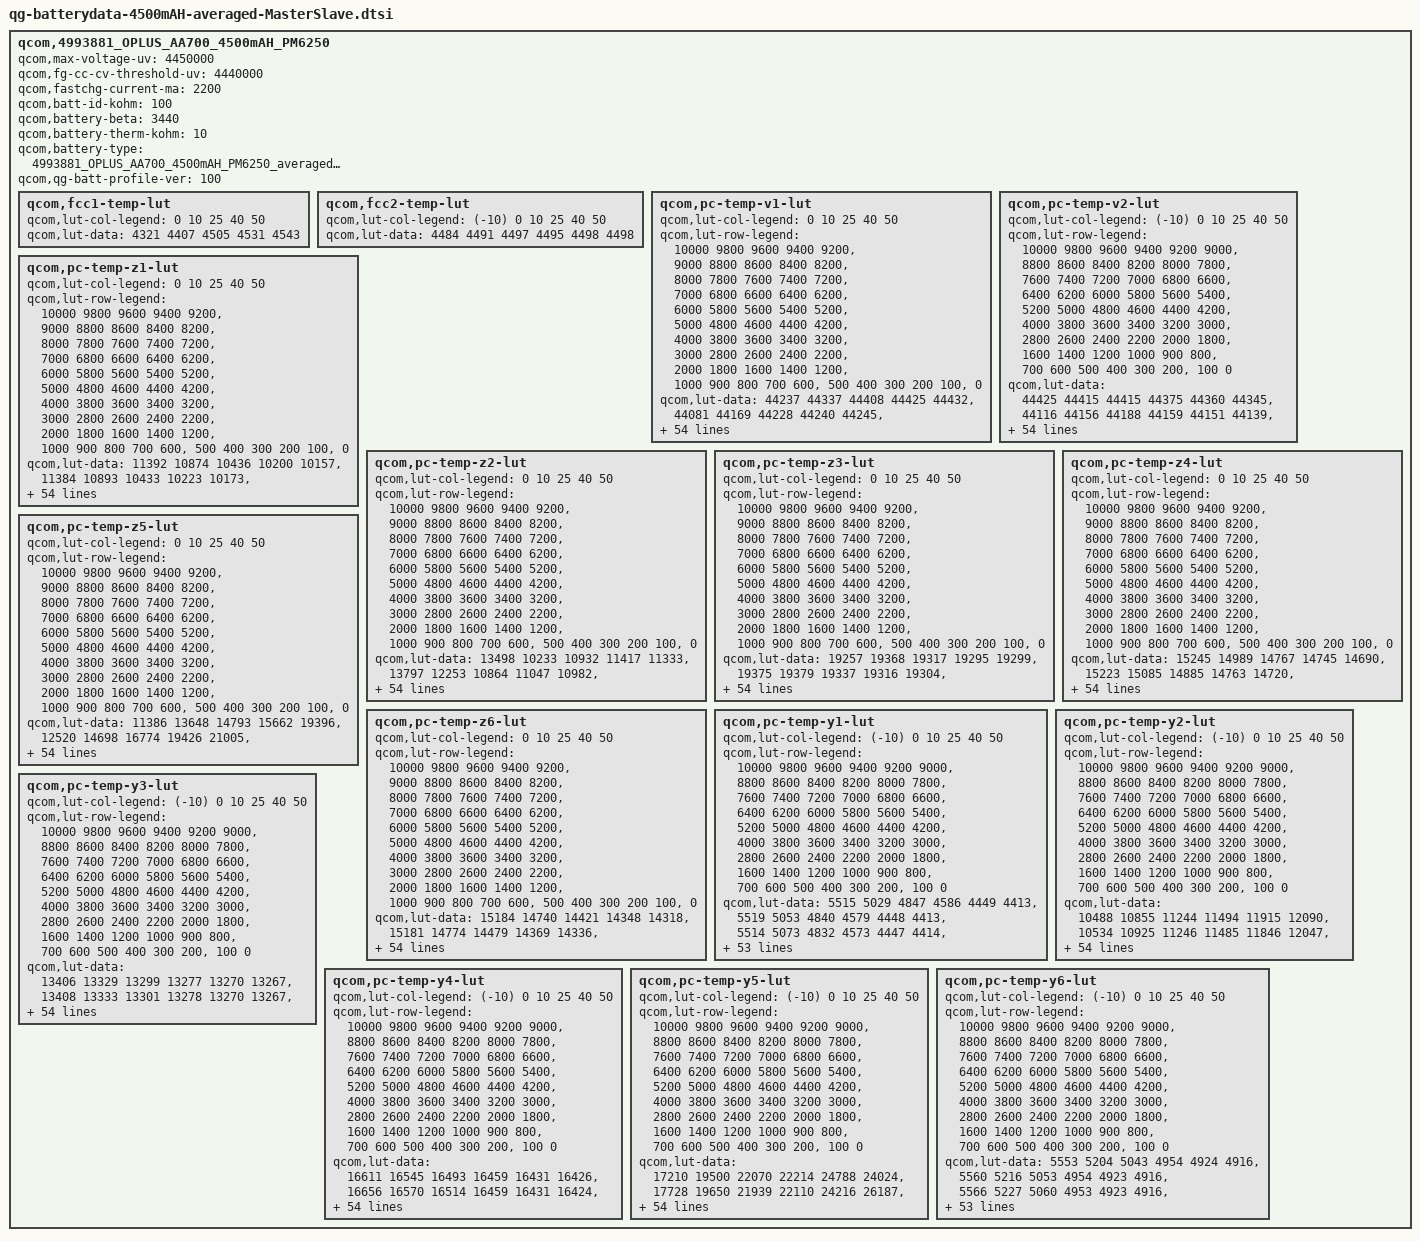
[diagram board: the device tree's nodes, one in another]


qcom,4993881_OPLUS_AA700_4500mAH_PM6250 {
    /* 4993881_OPLUS_AA700_4500mAH_PM6250_averaged_MasterSlave_Feb2th2021 */
    qcom,max-voltage-uv = <4450000>;
    qcom,fg-cc-cv-threshold-uv = <4440000>;
    qcom,fastchg-current-ma = <2200>;
    qcom,batt-id-kohm = <100>;
    qcom,battery-beta = <3440>;
    qcom,battery-therm-kohm = <10>;
    qcom,battery-type = "4993881_OPLUS_AA700_4500mAH_PM6250_averaged_MasterSlave_Feb2th2021";
    qcom,qg-batt-profile-ver = <100>;

	qcom,fcc1-temp-lut {
		qcom,lut-col-legend = <0 10 25 40 50>;
		qcom,lut-data = <4321 4407 4505 4531 4543>;
	};

	qcom,fcc2-temp-lut {
		qcom,lut-col-legend = <(-10) 0 10 25 40 50>;
		qcom,lut-data = <4484 4491 4497 4495 4498 4498>;
	};

	qcom,pc-temp-v1-lut {
		qcom,lut-col-legend = <0 10 25 40 50>;
		qcom,lut-row-legend = <10000 9800 9600 9400 9200>,
			<9000 8800 8600 8400 8200>,
			<8000 7800 7600 7400 7200>,
			<7000 6800 6600 6400 6200>,
			<6000 5800 5600 5400 5200>,
			<5000 4800 4600 4400 4200>,
			<4000 3800 3600 3400 3200>,
			<3000 2800 2600 2400 2200>,
			<2000 1800 1600 1400 1200>,
			<1000 900 800 700 600>,
			<500 400 300 200 100>,
			<0>;
		qcom,lut-data = <44237 44337 44408 44425 44432>,
			<44081 44169 44228 44240 44245>,
			<43870 43985 44048 44060 44064>,
			<43642 43785 43860 43875 43880>,
			<43419 43574 43663 43680 43689>,
			<43193 43355 43456 43476 43489>,
			<42962 43127 43233 43260 43276>,
			<42726 42893 42999 43032 43049>,
			<42489 42653 42762 42798 42816>,
			<42256 42411 42517 42556 42578>,
			<42025 42172 42273 42311 42338>,
			<41799 41935 42032 42071 42098>,
			<41577 41704 41793 41834 41858>,
			<41362 41479 41560 41599 41622>,
			<41154 41260 41333 41369 41390>,
			<40957 41052 41113 41143 41163>,
			<40760 40850 40900 40925 40944>,
			<40558 40651 40694 40715 40734>,
			<40356 40462 40497 40514 40532>,
			<40150 40269 40317 40330 40345>,
			<39937 40046 40122 40140 40156>,
			<39724 39787 39868 39902 39927>,
			<39514 39555 39592 39632 39661>,
			<39302 39367 39377 39406 39430>,
			<39138 39204 39207 39225 39245>,
			<39033 39062 39058 39068 39084>,
			<38949 38937 38926 38930 38942>,
			<38863 38826 38808 38807 38815>,
			<38776 38725 38698 38693 38698>,
			<38692 38632 38595 38586 38588>,
			<38616 38549 38502 38487 38486>,
			<38544 38473 38418 38397 38392>,
			<38480 38404 38342 38314 38305>,
			<38423 38343 38274 38240 38225>,
			<38371 38288 38214 38175 38155>,
			<38327 38236 38157 38109 38083>,
			<38289 38193 38102 38037 37996>,
			<38240 38144 38046 37957 37899>,
			<38155 38066 37970 37869 37799>,
			<38038 37954 37867 37770 37696>,
			<37910 37830 37750 37659 37584>,
			<37762 37696 37622 37529 37450>,
			<37595 37545 37478 37383 37303>,
			<37406 37361 37297 37212 37139>,
			<37306 37210 37152 37082 37014>,
			<37220 37128 37078 37015 36956>,
			<37187 37102 37054 36996 36938>,
			<37156 37083 37035 36985 36924>,
			<37114 37057 37005 36957 36892>,
			<36985 36954 36869 36795 36698>,
			<36604 36603 36502 36434 36324>,
			<36097 36118 36016 35951 35838>,
			<35446 35490 35384 35331 35207>,
			<34546 34625 34511 34457 34336>,
			<33087 33238 33127 33104 32965>,
			<30000 30000 30000 30000 30000>;
	};

	qcom,pc-temp-v2-lut {
		qcom,lut-col-legend = <(-10) 0 10 25 40 50>;
		qcom,lut-row-legend = <10000 9800 9600 9400 9200 9000>,
			<8800 8600 8400 8200 8000 7800>,
			<7600 7400 7200 7000 6800 6600>,
			<6400 6200 6000 5800 5600 5400>,
			<5200 5000 4800 4600 4400 4200>,
			<4000 3800 3600 3400 3200 3000>,
			<2800 2600 2400 2200 2000 1800>,
			<1600 1400 1200 1000 900 800>,
			<700 600 500 400 300 200>,
			<100 0>;
		qcom,lut-data = <44425 44415 44415 44375 44360 44345>,
			<44116 44156 44188 44159 44151 44139>,
			<43830 43912 43968 43947 43944 43934>,
			<43572 43688 43760 43741 43741 43732>,
			<43341 43484 43566 43542 43542 43532>,
			<43113 43276 43363 43336 43335 43325>,
			<42879 43048 43139 43113 43113 43104>,
			<42643 42810 42904 42879 42881 42873>,
			<42399 42570 42667 42642 42646 42640>,
			<42143 42327 42424 42398 42405 42399>,
			<41888 42084 42181 42155 42164 42159>,
			<41628 41842 41942 41915 41925 41921>,
			<41378 41602 41705 41677 41688 41684>,
			<41189 41367 41470 41444 41455 41452>,
			<41057 41135 41239 41217 41227 41225>,
			<40900 40919 41014 40995 41004 41003>,
			<40612 40740 40804 40781 40790 40787>,
			<40241 40568 40599 40573 40582 40578>,
			<39941 40342 40385 40371 40383 40379>,
			<39695 40042 40165 40180 40194 40193>,
			<39466 39746 39931 39973 39990 39990>,
			<39240 39492 39665 39710 39730 39731>,
			<39023 39258 39394 39429 39455 39456>,
			<38821 39054 39178 39209 39239 39243>,
			<38623 38872 39001 39030 39063 39071>,
			<38462 38710 38843 38874 38909 38921>,
			<38351 38567 38701 38737 38775 38787>,
			<38263 38438 38572 38616 38655 38666>,
			<38188 38314 38454 38502 38542 38553>,
			<38124 38190 38344 38397 38436 38447>,
			<38065 38089 38244 38300 38339 38349>,
			<38008 38019 38150 38211 38251 38259>,
			<37954 37962 38064 38128 38170 38175>,
			<37895 37912 37982 38048 38088 38089>,
			<37835 37869 37904 37972 38007 38005>,
			<37770 37827 37834 37892 37918 37909>,
			<37700 37786 37778 37802 37805 37782>,
			<37624 37742 37726 37705 37681 37641>,
			<37540 37680 37658 37610 37572 37524>,
			<37446 37588 37574 37518 37476 37427>,
			<37340 37475 37473 37417 37373 37325>,
			<37213 37331 37348 37303 37254 37203>,
			<37077 37162 37202 37173 37121 37068>,
			<36960 36977 37028 37002 36953 36900>,
			<36858 36843 36908 36908 36873 36825>,
			<36771 36774 36845 36873 36847 36801>,
			<36730 36742 36819 36856 36832 36785>,
			<36681 36707 36789 36829 36809 36760>,
			<36603 36647 36737 36782 36764 36700>,
			<36443 36482 36583 36627 36571 36454>,
			<36116 36111 36215 36249 36169 36031>,
			<35619 35566 35674 35723 35637 35483>,
			<34920 34851 34968 35050 34947 34761>,
			<33929 33850 33986 34122 33992 33773>,
			<32235 32088 32385 32620 32537 32234>,
			<27198 27147 28411 28035 28518 28018>;
	};

	qcom,pc-temp-z1-lut {
		qcom,lut-col-legend = <0 10 25 40 50>;
		qcom,lut-row-legend = <10000 9800 9600 9400 9200>,
			<9000 8800 8600 8400 8200>,
			<8000 7800 7600 7400 7200>,
			<7000 6800 6600 6400 6200>,
			<6000 5800 5600 5400 5200>,
			<5000 4800 4600 4400 4200>,
			<4000 3800 3600 3400 3200>,
			<3000 2800 2600 2400 2200>,
			<2000 1800 1600 1400 1200>,
			<1000 900 800 700 600>,
			<500 400 300 200 100>,
			<0>;
		qcom,lut-data = <11392 10874 10436 10200 10157>,
			<11384 10893 10433 10223 10173>,
			<11404 10895 10450 10230 10177>,
			<11419 10888 10452 10232 10178>,
			<11411 10878 10443 10230 10178>,
			<11389 10866 10432 10228 10178>,
			<11364 10852 10427 10226 10177>,
			<11331 10838 10424 10225 10176>,
			<11299 10825 10419 10223 10175>,
			<11280 10815 10414 10221 10174>,
			<11265 10809 10410 10219 10173>,
			<11257 10805 10408 10218 10173>,
			<11251 10801 10406 10218 10173>,
			<11246 10797 10405 10218 10173>,
			<11244 10793 10404 10217 10173>,
			<11242 10794 10403 10217 10173>,
			<11240 10800 10403 10217 10173>,
			<11242 10802 10403 10217 10173>,
			<11251 10794 10403 10217 10174>,
			<11255 10785 10406 10218 10174>,
			<11243 10792 10409 10220 10176>,
			<11229 10830 10411 10220 10176>,
			<11228 10854 10413 10220 10177>,
			<11232 10839 10415 10221 10178>,
			<11235 10814 10417 10222 10179>,
			<11236 10809 10420 10223 10181>,
			<11237 10805 10425 10225 10182>,
			<11239 10804 10431 10228 10182>,
			<11248 10809 10434 10230 10184>,
			<11256 10815 10436 10233 10185>,
			<11254 10817 10437 10235 10187>,
			<11250 10815 10440 10237 10189>,
			<11248 10814 10444 10239 10190>,
			<11250 10817 10449 10241 10191>,
			<11253 10823 10456 10244 10194>,
			<11257 10829 10463 10247 10196>,
			<11263 10837 10469 10250 10198>,
			<11271 10845 10474 10253 10200>,
			<11288 10851 10478 10255 10202>,
			<11310 10858 10481 10258 10203>,
			<11316 10862 10485 10260 10204>,
			<11304 10874 10490 10260 10205>,
			<11302 10882 10494 10261 10205>,
			<11310 10880 10497 10262 10206>,
			<11321 10887 10502 10264 10207>,
			<11317 10880 10505 10264 10207>,
			<11326 10901 10507 10265 10206>,
			<11340 10894 10516 10266 10208>,
			<11344 10893 10512 10268 10208>,
			<11343 10894 10519 10269 10209>,
			<11346 10896 10529 10271 10212>,
			<11356 10908 10531 10275 10213>,
			<11392 10915 10538 10279 10216>,
			<11380 10933 10542 10284 10220>,
			<11380 10933 10542 10284 10220>,
			<11380 10933 10542 10284 10220>;
	};

	qcom,pc-temp-z2-lut {
		qcom,lut-col-legend = <0 10 25 40 50>;
		qcom,lut-row-legend = <10000 9800 9600 9400 9200>,
			<9000 8800 8600 8400 8200>,
			<8000 7800 7600 7400 7200>,
			<7000 6800 6600 6400 6200>,
			<6000 5800 5600 5400 5200>,
			<5000 4800 4600 4400 4200>,
			<4000 3800 3600 3400 3200>,
			<3000 2800 2600 2400 2200>,
			<2000 1800 1600 1400 1200>,
			<1000 900 800 700 600>,
			<500 400 300 200 100>,
			<0>;
		qcom,lut-data = <13498 10233 10932 11417 11333>,
			<13797 12253 10864 11047 10982>,
			<11927 12575 10864 10953 11035>,
			<10471 11519 10844 10906 11073>,
			<10397 10623 10795 10872 11052>,
			<10387 10560 10757 10852 11016>,
			<10375 10520 10749 10857 11010>,
			<10355 10509 10744 10881 11015>,
			<10337 10508 10739 10893 11021>,
			<10330 10509 10736 10887 11036>,
			<10326 10516 10737 10883 11057>,
			<10324 10532 10741 10891 11065>,
			<10340 10540 10744 10908 11072>,
			<10369 10541 10736 10927 11081>,
			<10385 10541 10717 10953 11092>,
			<10394 10543 10698 10974 11107>,
			<10402 10550 10681 10973 11132>,
			<10410 10556 10666 10966 11172>,
			<10418 10561 10665 10960 11195>,
			<10430 10569 10678 10951 11193>,
			<10454 11228 10695 10943 11182>,
			<10475 13969 10717 10949 11161>,
			<10467 15631 10743 10964 11118>,
			<10425 13871 10764 10963 11064>,
			<10399 11170 10783 10874 10970>,
			<10411 10582 10794 10779 10888>,
			<10432 10567 10762 10754 10873>,
			<10439 10560 10706 10740 10873>,
			<10439 10557 10694 10741 10881>,
			<10439 10556 10700 10790 10935>,
			<10445 10561 10710 10850 11006>,
			<10460 10581 10744 10885 11060>,
			<10472 10602 10796 10915 11110>,
			<10483 10615 10819 10940 11138>,
			<10491 10626 10828 10960 11156>,
			<10491 10632 10835 10982 11176>,
			<10489 10634 10844 11024 11235>,
			<10488 10637 10854 11078 11323>,
			<10492 10650 10878 11118 11345>,
			<10499 10680 10936 11171 11327>,
			<10496 10691 10972 11204 11305>,
			<10474 10647 10919 11167 11287>,
			<10466 10614 10857 11104 11262>,
			<10472 10610 10867 11072 11199>,
			<14727 10645 10873 11073 11187>,
			<14065 10663 10878 11146 11248>,
			<16754 10642 10876 11144 11289>,
			<17754 10623 10803 11214 11332>,
			<18890 10616 10848 11179 11414>,
			<17901 10680 10865 11017 11094>,
			<14975 10727 10840 10939 10998>,
			<15650 10776 10792 10914 10932>,
			<12253 10753 10790 10852 10891>,
			<11025 10756 10700 10788 10813>,
			<11025 10756 10700 10788 10813>,
			<11025 10756 10700 10788 10813>;
	};

	qcom,pc-temp-z3-lut {
		qcom,lut-col-legend = <0 10 25 40 50>;
		qcom,lut-row-legend = <10000 9800 9600 9400 9200>,
			<9000 8800 8600 8400 8200>,
			<8000 7800 7600 7400 7200>,
			<7000 6800 6600 6400 6200>,
			<6000 5800 5600 5400 5200>,
			<5000 4800 4600 4400 4200>,
			<4000 3800 3600 3400 3200>,
			<3000 2800 2600 2400 2200>,
			<2000 1800 1600 1400 1200>,
			<1000 900 800 700 600>,
			<500 400 300 200 100>,
			<0>;
		qcom,lut-data = <19257 19368 19317 19295 19299>,
			<19375 19379 19337 19316 19304>,
			<19477 19392 19358 19321 19310>,
			<19541 19428 19368 19325 19313>,
			<19561 19458 19374 19330 19314>,
			<19572 19463 19377 19334 19315>,
			<19575 19467 19375 19333 19315>,
			<19576 19467 19372 19329 19315>,
			<19576 19463 19369 19325 19313>,
			<19575 19458 19367 19325 19311>,
			<19572 19455 19365 19324 19307>,
			<19568 19454 19364 19321 19306>,
			<19561 19452 19363 19317 19305>,
			<19554 19449 19360 19314 19305>,
			<19548 19445 19356 19314 19304>,
			<19542 19442 19352 19313 19304>,
			<19538 19439 19351 19312 19302>,
			<19536 19436 19350 19311 19298>,
			<19535 19434 19349 19310 19295>,
			<19535 19432 19347 19309 19294>,
			<19544 19430 19347 19308 19294>,
			<19555 19428 19347 19311 19298>,
			<19556 19428 19350 19322 19311>,
			<19549 19429 19355 19328 19317>,
			<19544 19434 19371 19331 19317>,
			<19542 19440 19382 19333 19317>,
			<19541 19453 19380 19332 19316>,
			<19541 19462 19378 19330 19314>,
			<19541 19459 19375 19329 19312>,
			<19542 19454 19371 19326 19310>,
			<19541 19449 19368 19324 19308>,
			<19538 19445 19364 19321 19306>,
			<19535 19441 19361 19317 19303>,
			<19534 19439 19359 19315 19301>,
			<19532 19437 19358 19313 19298>,
			<19530 19436 19357 19312 19296>,
			<19527 19435 19357 19312 19297>,
			<19524 19435 19357 19314 19301>,
			<19518 19433 19357 19315 19303>,
			<19512 19427 19355 19316 19306>,
			<19508 19423 19352 19316 19307>,
			<19506 19420 19348 19316 19306>,
			<19503 19416 19345 19317 19305>,
			<19496 19411 19345 19318 19305>,
			<19301 19401 19341 19315 19304>,
			<19257 19392 19331 19306 19295>,
			<19257 19391 19331 19306 19294>,
			<19257 19385 19330 19299 19291>,
			<19256 19377 19330 19299 19290>,
			<19256 19374 19332 19311 19301>,
			<19257 19373 19341 19314 19302>,
			<19257 19349 19338 19315 19302>,
			<19258 19340 19331 19313 19302>,
			<19259 19333 19339 19317 19306>,
			<19259 19333 19339 19317 19306>,
			<19259 19333 19339 19317 19306>;
	};

	qcom,pc-temp-z4-lut {
		qcom,lut-col-legend = <0 10 25 40 50>;
		qcom,lut-row-legend = <10000 9800 9600 9400 9200>,
			<9000 8800 8600 8400 8200>,
			<8000 7800 7600 7400 7200>,
			<7000 6800 6600 6400 6200>,
			<6000 5800 5600 5400 5200>,
			<5000 4800 4600 4400 4200>,
			<4000 3800 3600 3400 3200>,
			<3000 2800 2600 2400 2200>,
			<2000 1800 1600 1400 1200>,
			<1000 900 800 700 600>,
			<500 400 300 200 100>,
			<0>;
		qcom,lut-data = <15245 14989 14767 14745 14690>,
			<15223 15085 14885 14763 14720>,
			<15219 15094 14864 14750 14712>,
			<15214 15030 14838 14735 14701>,
			<15173 14955 14801 14712 14686>,
			<15076 14901 14766 14691 14669>,
			<14994 14852 14741 14681 14661>,
			<14934 14812 14720 14675 14657>,
			<14884 14776 14708 14670 14654>,
			<14844 14751 14701 14665 14652>,
			<14809 14742 14695 14660 14650>,
			<14786 14736 14688 14656 14647>,
			<14773 14732 14682 14654 14642>,
			<14763 14729 14678 14650 14638>,
			<14759 14727 14676 14645 14633>,
			<14757 14725 14674 14640 14629>,
			<14755 14722 14672 14636 14626>,
			<14762 14721 14669 14633 14624>,
			<14778 14723 14668 14631 14622>,
			<14790 14728 14668 14630 14620>,
			<14797 14742 14668 14629 14619>,
			<14805 14779 14701 14643 14626>,
			<14825 14806 14761 14679 14651>,
			<14866 14817 14772 14692 14663>,
			<14889 14824 14750 14686 14661>,
			<14875 14820 14727 14677 14657>,
			<14848 14791 14715 14671 14653>,
			<14830 14767 14706 14664 14648>,
			<14817 14762 14701 14659 14644>,
			<14809 14759 14696 14654 14640>,
			<14807 14759 14695 14650 14637>,
			<14806 14760 14695 14648 14634>,
			<14806 14761 14695 14647 14631>,
			<14807 14762 14696 14646 14631>,
			<14807 14762 14698 14647 14631>,
			<14804 14762 14701 14648 14631>,
			<14798 14759 14704 14654 14636>,
			<14791 14755 14708 14664 14645>,
			<14784 14752 14709 14666 14647>,
			<14777 14747 14706 14663 14644>,
			<14766 14741 14702 14659 14640>,
			<14748 14725 14691 14653 14638>,
			<14729 14708 14678 14647 14636>,
			<14710 14695 14672 14645 14636>,
			<14840 14668 14658 14640 14630>,
			<14863 14644 14640 14629 14622>,
			<14860 14638 14630 14621 14616>,
			<14855 14638 14623 14618 14610>,
			<14853 14640 14620 14614 14609>,
			<14852 14645 14626 14615 14612>,
			<14858 14651 14620 14614 14613>,
			<14860 14677 14622 14614 14613>,
			<14866 14690 14627 14615 14613>,
			<14873 14699 14621 14614 14613>,
			<14873 14699 14621 14614 14613>,
			<14873 14699 14621 14614 14613>;
	};

	qcom,pc-temp-z5-lut {
		qcom,lut-col-legend = <0 10 25 40 50>;
		qcom,lut-row-legend = <10000 9800 9600 9400 9200>,
			<9000 8800 8600 8400 8200>,
			<8000 7800 7600 7400 7200>,
			<7000 6800 6600 6400 6200>,
			<6000 5800 5600 5400 5200>,
			<5000 4800 4600 4400 4200>,
			<4000 3800 3600 3400 3200>,
			<3000 2800 2600 2400 2200>,
			<2000 1800 1600 1400 1200>,
			<1000 900 800 700 600>,
			<500 400 300 200 100>,
			<0>;
		qcom,lut-data = <11386 13648 14793 15662 19396>,
			<12520 14698 16774 19426 21005>,
			<15114 15828 18476 20080 22131>,
			<17682 17836 19502 20827 23002>,
			<19048 19806 20178 22500 24107>,
			<20037 20948 20756 23953 25213>,
			<21167 21872 21486 23974 25996>,
			<22549 23068 22234 23536 26656>,
			<24094 24827 22605 23349 26951>,
			<25845 26499 22949 24001 26251>,
			<27871 27644 23304 24745 25170>,
			<29700 28590 23955 24464 25022>,
			<31359 29099 24789 23377 25613>,
			<32724 29394 24909 22944 26307>,
			<33140 29566 24392 23902 27927>,
			<33039 29642 23996 25140 29729>,
			<32981 29837 24348 25836 29453>,
			<33670 29860 25107 26561 27427>,
			<35041 29255 25647 26921 26398>,
			<36210 28547 26092 27536 27421>,
			<39115 28538 26318 28104 28680>,
			<42270 28943 24725 26733 28187>,
			<42005 29183 21907 23070 25823>,
			<38458 27168 21348 21694 24024>,
			<35458 24082 22161 21677 22948>,
			<34122 24106 23283 21712 22274>,
			<33079 28405 24646 22253 22563>,
			<33141 32788 26427 23754 23749>,
			<35304 35128 28294 25386 24978>,
			<37985 36962 30489 27349 26213>,
			<40032 38283 32465 29175 27536>,
			<41967 39362 34055 30377 29046>,
			<43081 40142 35541 31338 30649>,
			<43690 40631 36854 32287 31340>,
			<44050 41023 38334 33468 31576>,
			<43934 41223 39123 34184 31635>,
			<43382 41346 38767 33572 31089>,
			<43038 41412 37954 32173 30062>,
			<42649 41001 37006 31424 30134>,
			<42009 39628 35079 31432 33416>,
			<41858 38298 33055 31672 36520>,
			<42050 37230 31297 32753 37037>,
			<42238 36194 30085 34158 36760>,
			<42213 34992 29730 33995 34088>,
			<17358 38949 30267 30953 32280>,
			<11542 39444 29739 28554 26480>,
			<11458 40544 34037 35726 30168>,
			<11422 35532 36739 32432 36920>,
			<11403 27469 39324 34969 37538>,
			<11441 25280 30470 43004 44201>,
			<11445 22853 36815 42191 43066>,
			<11398 16663 30847 44835 39521>,
			<11340 15125 24381 36790 38769>,
			<11273 14580 30215 42547 45518>,
			<11273 14580 30215 42547 45518>,
			<11273 14580 30215 42547 45518>;
	};

	qcom,pc-temp-z6-lut {
		qcom,lut-col-legend = <0 10 25 40 50>;
		qcom,lut-row-legend = <10000 9800 9600 9400 9200>,
			<9000 8800 8600 8400 8200>,
			<8000 7800 7600 7400 7200>,
			<7000 6800 6600 6400 6200>,
			<6000 5800 5600 5400 5200>,
			<5000 4800 4600 4400 4200>,
			<4000 3800 3600 3400 3200>,
			<3000 2800 2600 2400 2200>,
			<2000 1800 1600 1400 1200>,
			<1000 900 800 700 600>,
			<500 400 300 200 100>,
			<0>;
		qcom,lut-data = <15184 14740 14421 14348 14318>,
			<15181 14774 14479 14369 14336>,
			<15185 14777 14481 14367 14336>,
			<15188 14753 14479 14366 14336>,
			<15161 14723 14464 14360 14331>,
			<15088 14695 14447 14352 14324>,
			<15023 14662 14433 14346 14320>,
			<14971 14635 14421 14341 14317>,
			<14925 14609 14413 14337 14315>,
			<14887 14589 14408 14334 14313>,
			<14855 14581 14403 14331 14310>,
			<14831 14575 14399 14328 14307>,
			<14815 14570 14396 14324 14305>,
			<14804 14566 14392 14321 14303>,
			<14796 14562 14389 14318 14301>,
			<14791 14558 14386 14316 14299>,
			<14788 14554 14384 14313 14296>,
			<14789 14552 14382 14311 14293>,
			<14793 14552 14381 14310 14291>,
			<14798 14552 14381 14309 14290>,
			<14804 14557 14381 14308 14289>,
			<14812 14578 14397 14317 14294>,
			<14823 14594 14425 14339 14313>,
			<14838 14598 14431 14347 14322>,
			<14846 14600 14430 14346 14321>,
			<14840 14600 14428 14344 14320>,
			<14830 14596 14425 14342 14318>,
			<14825 14592 14419 14338 14315>,
			<14821 14589 14415 14335 14312>,
			<14820 14586 14413 14332 14310>,
			<14820 14585 14411 14329 14307>,
			<14821 14585 14409 14327 14305>,
			<14821 14585 14408 14324 14302>,
			<14823 14585 14408 14323 14301>,
			<14825 14587 14410 14323 14299>,
			<14826 14588 14412 14323 14298>,
			<14827 14590 14415 14326 14301>,
			<14827 14591 14418 14332 14308>,
			<14828 14591 14419 14333 14310>,
			<14829 14590 14418 14333 14309>,
			<14830 14589 14416 14332 14309>,
			<14829 14585 14411 14329 14308>,
			<14829 14581 14405 14327 14307>,
			<14830 14578 14403 14327 14307>,
			<14805 14569 14397 14324 14304>,
			<14796 14559 14386 14315 14296>,
			<14798 14556 14382 14311 14292>,
			<14798 14554 14378 14306 14288>,
			<14801 14554 14379 14304 14287>,
			<14810 14559 14384 14312 14295>,
			<14820 14566 14388 14313 14296>,
			<14829 14570 14389 14315 14297>,
			<14841 14576 14390 14315 14298>,
			<14859 14585 14394 14318 14301>,
			<14859 14585 14394 14318 14301>,
			<14859 14585 14394 14318 14301>;
	};

	qcom,pc-temp-y1-lut {
		qcom,lut-col-legend = <(-10) 0 10 25 40 50>;
		qcom,lut-row-legend = <10000 9800 9600 9400 9200 9000>,
			<8800 8600 8400 8200 8000 7800>,
			<7600 7400 7200 7000 6800 6600>,
			<6400 6200 6000 5800 5600 5400>,
			<5200 5000 4800 4600 4400 4200>,
			<4000 3800 3600 3400 3200 3000>,
			<2800 2600 2400 2200 2000 1800>,
			<1600 1400 1200 1000 900 800>,
			<700 600 500 400 300 200>,
			<100 0>;
		qcom,lut-data = <5515 5029 4847 4586 4449 4413>,
			<5519 5053 4840 4579 4448 4413>,
			<5514 5073 4832 4573 4447 4414>,
			<5504 5088 4825 4568 4445 4414>,
			<5494 5098 4818 4563 4443 4413>,
			<5490 5102 4814 4559 4442 4413>,
			<5487 5097 4812 4556 4441 4412>,
			<5483 5088 4811 4554 4440 4412>,
			<5484 5084 4811 4552 4440 4411>,
			<5491 5082 4808 4551 4438 4412>,
			<5496 5081 4805 4550 4437 4412>,
			<5491 5079 4800 4549 4437 4411>,
			<5483 5077 4793 4547 4437 4409>,
			<5483 5077 4790 4546 4436 4409>,
			<5495 5076 4790 4544 4435 4409>,
			<5505 5075 4790 4542 4434 4409>,
			<5516 5072 4787 4542 4434 4409>,
			<5530 5067 4784 4542 4434 4409>,
			<5533 5067 4784 4542 4434 4409>,
			<5527 5069 4789 4543 4434 4409>,
			<5523 5072 4793 4545 4435 4409>,
			<5525 5078 4794 4546 4435 4410>,
			<5528 5088 4795 4548 4435 4410>,
			<5529 5095 4795 4549 4436 4411>,
			<5524 5101 4796 4551 4436 4411>,
			<5519 5105 4797 4553 4437 4411>,
			<5527 5101 4796 4556 4438 4411>,
			<5543 5096 4794 4558 4440 4412>,
			<5545 5094 4795 4561 4441 4412>,
			<5521 5094 4800 4564 4441 4413>,
			<5501 5095 4805 4566 4442 4414>,
			<5507 5094 4808 4568 4443 4415>,
			<5519 5094 4811 4571 4445 4416>,
			<5520 5095 4814 4574 4446 4416>,
			<5504 5099 4821 4579 4446 4416>,
			<5491 5102 4826 4582 4447 4417>,
			<5502 5100 4821 4583 4448 4418>,
			<5524 5098 4813 4584 4449 4419>,
			<5532 5099 4813 4585 4451 4420>,
			<5532 5103 4819 4589 4452 4421>,
			<5531 5105 4825 4592 4453 4421>,
			<5535 5110 4828 4593 4455 4421>,
			<5537 5117 4832 4595 4456 4422>,
			<5521 5100 4849 4597 4456 4422>,
			<5508 5107 4853 4602 4456 4423>,
			<5545 5107 4861 4606 4459 4425>,
			<5573 5100 4865 4610 4460 4423>,
			<5561 5112 4860 4607 4458 4425>,
			<5551 5111 4857 4614 4459 4423>,
			<5574 5111 4874 4614 4459 4425>,
			<5607 5134 4868 4614 4459 4426>,
			<5616 5132 4872 4618 4461 4426>,
			<5664 5144 4867 4627 4462 4428>,
			<5777 5191 4874 4641 4467 4431>,
			<5777 5191 4874 4641 4467 4431>,
			<5777 5191 4874 4641 4467 4431>;
	};

	qcom,pc-temp-y2-lut {
		qcom,lut-col-legend = <(-10) 0 10 25 40 50>;
		qcom,lut-row-legend = <10000 9800 9600 9400 9200 9000>,
			<8800 8600 8400 8200 8000 7800>,
			<7600 7400 7200 7000 6800 6600>,
			<6400 6200 6000 5800 5600 5400>,
			<5200 5000 4800 4600 4400 4200>,
			<4000 3800 3600 3400 3200 3000>,
			<2800 2600 2400 2200 2000 1800>,
			<1600 1400 1200 1000 900 800>,
			<700 600 500 400 300 200>,
			<100 0>;
		qcom,lut-data = <10488 10855 11244 11494 11915 12090>,
			<10534 10925 11246 11485 11846 12047>,
			<10599 10975 11240 11466 11778 11995>,
			<10666 11008 11228 11443 11714 11934>,
			<10723 11026 11211 11420 11657 11868>,
			<10754 11031 11193 11401 11610 11798>,
			<10764 11015 11166 11372 11573 11708>,
			<10770 10988 11135 11333 11540 11620>,
			<10770 10979 11114 11308 11504 11586>,
			<10760 10976 11098 11282 11456 11567>,
			<10753 10975 11090 11265 11431 11556>,
			<10792 10982 11093 11257 11452 11557>,
			<10862 10997 11101 11252 11484 11562>,
			<10893 11014 11114 11254 11486 11555>,
			<10905 11040 11146 11270 11464 11528>,
			<10917 11071 11190 11294 11444 11512>,
			<10940 11126 11255 11328 11434 11529>,
			<10964 11184 11332 11377 11428 11567>,
			<10963 11201 11390 11458 11447 11614>,
			<10925 11205 11442 11612 11553 11686>,
			<10884 11205 11465 11703 11649 11740>,
			<10862 11187 11410 11654 11699 11764>,
			<10840 11155 11324 11565 11736 11785>,
			<10743 11133 11309 11520 11746 11817>,
			<10308 11116 11329 11488 11746 11887>,
			<9931 11108 11342 11473 11746 11948>,
			<9827 11115 11339 11500 11756 11987>,
			<9756 11126 11334 11546 11776 12019>,
			<9728 11125 11334 11561 11802 12038>,
			<9714 11103 11344 11582 11856 12055>,
			<9705 11081 11350 11606 11907 12071>,
			<9699 11075 11335 11633 11946 12111>,
			<9694 11069 11311 11654 11976 12171>,
			<9689 11000 11306 11659 11985 12213>,
			<9685 10680 11315 11667 11986 12277>,
			<9680 10462 11320 11673 11982 12313>,
			<9677 10614 11311 11659 11959 12258>,
			<9675 10857 11292 11634 11924 12160>,
			<9673 10850 11269 11620 11905 12101>,
			<9671 10643 11234 11605 11888 12036>,
			<9669 10397 11186 11590 11880 12000>,
			<9668 10078 11094 11576 11909 11975>,
			<9667 9800 10971 11557 11937 11948>,
			<9666 9724 10855 11496 11903 12015>,
			<9664 9697 10709 11429 11810 12013>,
			<9663 9687 10554 11380 11821 11786>,
			<9661 9681 10508 11418 11725 11738>,
			<9661 9677 10414 11327 11672 11721>,
			<9659 9672 10410 11358 11581 11661>,
			<9658 9669 10357 11343 11618 11733>,
			<9656 9665 10116 11320 11585 11675>,
			<9652 9662 10006 11245 11523 11597>,
			<9649 9658 9848 11236 11457 11509>,
			<9648 9652 9720 11177 11324 11341>,
			<9648 9652 9720 11177 11324 11341>,
			<9648 9652 9720 11177 11324 11341>;
	};

	qcom,pc-temp-y3-lut {
		qcom,lut-col-legend = <(-10) 0 10 25 40 50>;
		qcom,lut-row-legend = <10000 9800 9600 9400 9200 9000>,
			<8800 8600 8400 8200 8000 7800>,
			<7600 7400 7200 7000 6800 6600>,
			<6400 6200 6000 5800 5600 5400>,
			<5200 5000 4800 4600 4400 4200>,
			<4000 3800 3600 3400 3200 3000>,
			<2800 2600 2400 2200 2000 1800>,
			<1600 1400 1200 1000 900 800>,
			<700 600 500 400 300 200>,
			<100 0>;
		qcom,lut-data = <13406 13329 13299 13277 13270 13267>,
			<13408 13333 13301 13278 13270 13267>,
			<13410 13337 13304 13279 13270 13268>,
			<13412 13341 13306 13280 13270 13268>,
			<13415 13344 13308 13280 13270 13268>,
			<13418 13347 13309 13281 13271 13269>,
			<13423 13349 13310 13282 13271 13269>,
			<13427 13350 13310 13282 13272 13269>,
			<13427 13352 13311 13283 13272 13269>,
			<13423 13354 13312 13282 13273 13270>,
			<13419 13356 13314 13282 13273 13270>,
			<13416 13356 13315 13283 13274 13271>,
			<13413 13355 13316 13283 13274 13271>,
			<13409 13354 13316 13284 13274 13271>,
			<13400 13348 13315 13285 13275 13272>,
			<13393 13343 13314 13286 13275 13272>,
			<13392 13340 13312 13287 13276 13272>,
			<13390 13338 13310 13289 13277 13272>,
			<13387 13336 13310 13289 13278 13272>,
			<13379 13334 13310 13288 13278 13273>,
			<13372 13332 13310 13288 13278 13274>,
			<13367 13328 13307 13286 13277 13272>,
			<13363 13324 13302 13283 13274 13269>,
			<13358 13321 13299 13281 13272 13268>,
			<13349 13319 13298 13279 13270 13267>,
			<13343 13317 13297 13279 13270 13267>,
			<13345 13316 13297 13279 13270 13267>,
			<13351 13315 13296 13278 13270 13268>,
			<13356 13314 13296 13278 13270 13268>,
			<13362 13311 13295 13278 13269 13267>,
			<13369 13309 13295 13278 13269 13267>,
			<13378 13308 13294 13278 13269 13267>,
			<13390 13308 13294 13279 13270 13267>,
			<13405 13308 13293 13279 13270 13267>,
			<13422 13309 13293 13278 13270 13268>,
			<13443 13310 13293 13278 13270 13268>,
			<13469 13315 13293 13278 13269 13268>,
			<13500 13322 13294 13277 13268 13267>,
			<13535 13326 13294 13276 13268 13267>,
			<13576 13330 13295 13275 13268 13267>,
			<13622 13334 13296 13274 13269 13268>,
			<13671 13343 13297 13275 13269 13268>,
			<13725 13356 13299 13275 13270 13268>,
			<13793 13371 13302 13275 13269 13267>,
			<13878 13393 13306 13276 13269 13267>,
			<13963 13421 13306 13278 13270 13269>,
			<14024 13438 13309 13279 13271 13269>,
			<14110 13472 13313 13279 13272 13270>,
			<14223 13520 13320 13283 13274 13270>,
			<14379 13575 13326 13284 13272 13269>,
			<14625 13655 13332 13283 13272 13269>,
			<15425 13802 13342 13284 13272 13270>,
			<17692 14086 13370 13287 13273 13270>,
			<23205 15006 13435 13292 13274 13271>,
			<23205 15006 13435 13292 13274 13271>,
			<23205 15006 13435 13292 13274 13271>;
	};

	qcom,pc-temp-y4-lut {
		qcom,lut-col-legend = <(-10) 0 10 25 40 50>;
		qcom,lut-row-legend = <10000 9800 9600 9400 9200 9000>,
			<8800 8600 8400 8200 8000 7800>,
			<7600 7400 7200 7000 6800 6600>,
			<6400 6200 6000 5800 5600 5400>,
			<5200 5000 4800 4600 4400 4200>,
			<4000 3800 3600 3400 3200 3000>,
			<2800 2600 2400 2200 2000 1800>,
			<1600 1400 1200 1000 900 800>,
			<700 600 500 400 300 200>,
			<100 0>;
		qcom,lut-data = <16611 16545 16493 16459 16431 16426>,
			<16656 16570 16514 16459 16431 16424>,
			<16727 16618 16537 16459 16430 16423>,
			<16806 16672 16559 16458 16429 16422>,
			<16871 16716 16575 16458 16429 16421>,
			<16904 16735 16581 16458 16428 16420>,
			<16911 16734 16578 16457 16428 16420>,
			<16915 16731 16572 16457 16427 16420>,
			<16916 16727 16568 16457 16427 16421>,
			<16916 16720 16564 16459 16428 16421>,
			<16917 16715 16562 16462 16429 16421>,
			<16922 16719 16564 16465 16431 16422>,
			<16932 16727 16567 16468 16433 16424>,
			<16966 16739 16573 16473 16436 16425>,
			<17089 16765 16587 16478 16439 16427>,
			<17172 16799 16606 16485 16444 16430>,
			<17088 16860 16645 16494 16448 16434>,
			<16923 16927 16689 16507 16454 16440>,
			<16838 16925 16696 16527 16465 16449>,
			<16795 16828 16693 16565 16487 16462>,
			<16756 16730 16687 16588 16500 16470>,
			<16707 16675 16640 16557 16485 16459>,
			<16658 16632 16566 16502 16459 16441>,
			<16628 16600 16534 16476 16445 16433>,
			<16608 16576 16517 16461 16436 16427>,
			<16598 16557 16508 16454 16432 16425>,
			<16600 16544 16503 16455 16433 16425>,
			<16603 16532 16500 16455 16434 16426>,
			<16604 16518 16499 16457 16435 16427>,
			<16609 16496 16499 16461 16438 16430>,
			<16615 16485 16498 16466 16442 16433>,
			<16619 16487 16498 16472 16448 16438>,
			<16626 16492 16498 16477 16454 16443>,
			<16632 16502 16496 16481 16459 16446>,
			<16640 16527 16486 16484 16462 16447>,
			<16649 16549 16480 16485 16464 16448>,
			<16657 16564 16484 16476 16455 16441>,
			<16665 16579 16492 16458 16440 16431>,
			<16669 16588 16497 16448 16435 16428>,
			<16671 16596 16499 16441 16433 16428>,
			<16672 16600 16503 16438 16432 16428>,
			<16664 16594 16508 16439 16429 16427>,
			<16650 16584 16514 16442 16425 16425>,
			<16647 16578 16520 16443 16421 16419>,
			<16653 16579 16527 16447 16421 16418>,
			<16660 16581 16522 16451 16425 16421>,
			<16669 16594 16534 16455 16428 16426>,
			<16698 16616 16551 16465 16433 16436>,
			<16732 16648 16572 16476 16451 16459>,
			<16740 16664 16587 16483 16442 16431>,
			<16724 16658 16588 16473 16425 16423>,
			<16793 16670 16596 16479 16430 16428>,
			<17246 16717 16631 16505 16442 16437>,
			<19410 16986 16704 16550 16478 16490>,
			<19410 16986 16704 16550 16478 16490>,
			<19410 16986 16704 16550 16478 16490>;
	};

	qcom,pc-temp-y5-lut {
		qcom,lut-col-legend = <(-10) 0 10 25 40 50>;
		qcom,lut-row-legend = <10000 9800 9600 9400 9200 9000>,
			<8800 8600 8400 8200 8000 7800>,
			<7600 7400 7200 7000 6800 6600>,
			<6400 6200 6000 5800 5600 5400>,
			<5200 5000 4800 4600 4400 4200>,
			<4000 3800 3600 3400 3200 3000>,
			<2800 2600 2400 2200 2000 1800>,
			<1600 1400 1200 1000 900 800>,
			<700 600 500 400 300 200>,
			<100 0>;
		qcom,lut-data = <17210 19500 22070 22214 24788 24024>,
			<17728 19650 21939 22110 24216 26187>,
			<18258 19872 21739 21951 23658 27454>,
			<18789 20109 21495 21745 23156 28046>,
			<19314 20302 21228 21501 22751 28183>,
			<19823 20395 20964 21224 22490 28085>,
			<20433 20409 20675 20930 22383 27364>,
			<20971 20408 20364 20581 22333 26276>,
			<20912 20380 20092 20000 22197 25836>,
			<19943 20265 19854 18827 21872 25581>,
			<18926 20079 19582 17845 21459 25256>,
			<18096 19464 19185 17320 20931 24726>,
			<17346 18394 18672 16922 20248 24006>,
			<17399 17334 18007 16689 19427 23199>,
			<18788 16077 16892 16470 18306 22231>,
			<20179 15413 16059 16294 17715 21135>,
			<21636 16415 15698 16137 17822 19522>,
			<23390 18485 15469 16001 17991 17973>,
			<23858 20208 16048 16026 17921 17721>,
			<23673 21877 19463 16394 17380 17867>,
			<23571 23007 22338 17025 17026 18108>,
			<23797 23527 23359 19395 19217 19061>,
			<24061 23863 24041 22649 22631 20619>,
			<23397 23956 24449 23567 23223 21785>,
			<18341 23927 24900 23769 22815 22827>,
			<14186 23930 25134 23833 22480 23476>,
			<13606 24427 25119 23801 22401 23758>,
			<13276 25202 25129 23697 22321 23935>,
			<13234 24974 25248 23454 21906 23656>,
			<13294 22309 25418 22995 20508 22021>,
			<13348 20000 25534 22732 19580 20420>,
			<13509 19414 25584 22983 19536 19380>,
			<13820 19002 25608 23393 19589 18592>,
			<14004 18619 25589 23572 19821 18938>,
			<14215 18492 25565 23813 20578 21512>,
			<14387 18638 25524 24189 21179 23218>,
			<14507 20380 25242 25376 21313 23162>,
			<14692 22975 24673 26925 21399 23068>,
			<14868 23538 23999 26771 21695 23245>,
			<15084 23351 23052 23860 22328 24495>,
			<15219 22940 22198 21545 23257 26057>,
			<14827 20828 21236 21162 25424 27759>,
			<14180 17783 20590 20853 27543 29218>,
			<13976 15748 20821 20765 28508 30681>,
			<13742 14959 20550 21919 27795 31006>,
			<13620 14943 19679 22392 24513 28957>,
			<13798 14509 18866 21520 24346 27549>,
			<13920 14495 18081 19227 24602 25798>,
			<14120 14539 17856 20566 26320 23527>,
			<14445 14831 18245 22910 25056 27468>,
			<14150 14816 18588 24896 33802 35198>,
			<13136 14629 17947 24212 31548 34065>,
			<11114 14571 17396 25054 30146 29642>,
			<9698 12850 16283 24787 27798 28271>,
			<9698 12850 16283 24787 27798 28271>,
			<9698 12850 16283 24787 27798 28271>;
	};

	qcom,pc-temp-y6-lut {
		qcom,lut-col-legend = <(-10) 0 10 25 40 50>;
		qcom,lut-row-legend = <10000 9800 9600 9400 9200 9000>,
			<8800 8600 8400 8200 8000 7800>,
			<7600 7400 7200 7000 6800 6600>,
			<6400 6200 6000 5800 5600 5400>,
			<5200 5000 4800 4600 4400 4200>,
			<4000 3800 3600 3400 3200 3000>,
			<2800 2600 2400 2200 2000 1800>,
			<1600 1400 1200 1000 900 800>,
			<700 600 500 400 300 200>,
			<100 0>;
		qcom,lut-data = <5553 5204 5043 4954 4924 4916>,
			<5560 5216 5053 4954 4923 4916>,
			<5566 5227 5060 4953 4923 4916>,
			<5571 5236 5064 4953 4923 4916>,
			<5574 5242 5066 4953 4923 4916>,
			<5576 5244 5067 4953 4923 4916>,
			<5575 5242 5065 4953 4923 4916>,
			<5573 5238 5061 4953 4923 4916>,
			<5570 5234 5058 4953 4923 4916>,
			<5564 5230 5056 4953 4924 4917>,
			<5559 5228 5055 4954 4925 4917>,
			<5555 5227 5055 4954 4925 4918>,
			<5553 5226 5055 4956 4926 4918>,
			<5557 5227 5055 4957 4927 4919>,
			<5587 5228 5058 4959 4928 4920>,
			<5609 5231 5061 4962 4930 4921>,
			<5588 5245 5070 4965 4931 4922>,
			<5546 5264 5080 4970 4934 4924>,
			<5522 5264 5082 4976 4937 4926>,
			<5508 5236 5081 4987 4944 4931>,
			<5496 5208 5079 4993 4948 4934>,
			<5484 5190 5063 4983 4942 4930>,
			<5473 5176 5039 4964 4932 4922>,
			<5464 5167 5029 4956 4927 4918>,
			<5455 5160 5023 4951 4924 4916>,
			<5451 5156 5021 4949 4922 4916>,
			<5456 5155 5020 4949 4922 4916>,
			<5468 5154 5020 4949 4923 4916>,
			<5481 5153 5020 4950 4923 4917>,
			<5495 5150 5021 4951 4924 4917>,
			<5512 5149 5022 4953 4925 4918>,
			<5531 5152 5023 4955 4927 4919>,
			<5555 5160 5024 4958 4929 4921>,
			<5579 5170 5024 4959 4930 4922>,
			<5605 5183 5023 4960 4932 4923>,
			<5634 5199 5023 4961 4932 4923>,
			<5666 5219 5025 4958 4929 4921>,
			<5702 5242 5030 4953 4925 4918>,
			<5740 5266 5035 4950 4923 4917>,
			<5782 5289 5040 4948 4923 4917>,
			<5825 5313 5045 4947 4923 4918>,
			<5869 5337 5054 4948 4922 4917>,
			<5917 5362 5066 4950 4922 4917>,
			<5979 5395 5081 4951 4920 4915>,
			<6059 5439 5099 4954 4920 4915>,
			<6145 5488 5103 4957 4923 4917>,
			<6205 5521 5116 4960 4924 4919>,
			<6294 5571 5134 4963 4927 4922>,
			<6407 5634 5158 4969 4933 4929>,
			<6559 5702 5182 4973 4929 4920>,
			<6793 5787 5207 4970 4924 4919>,
			<7538 5934 5249 4974 4926 4920>,
			<9500 6218 5327 4986 4930 4923>,
			<13981 7114 5453 5005 4941 4939>,
			<13981 7114 5453 5005 4941 4939>,
			<13981 7114 5453 5005 4941 4939>;
	};

};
